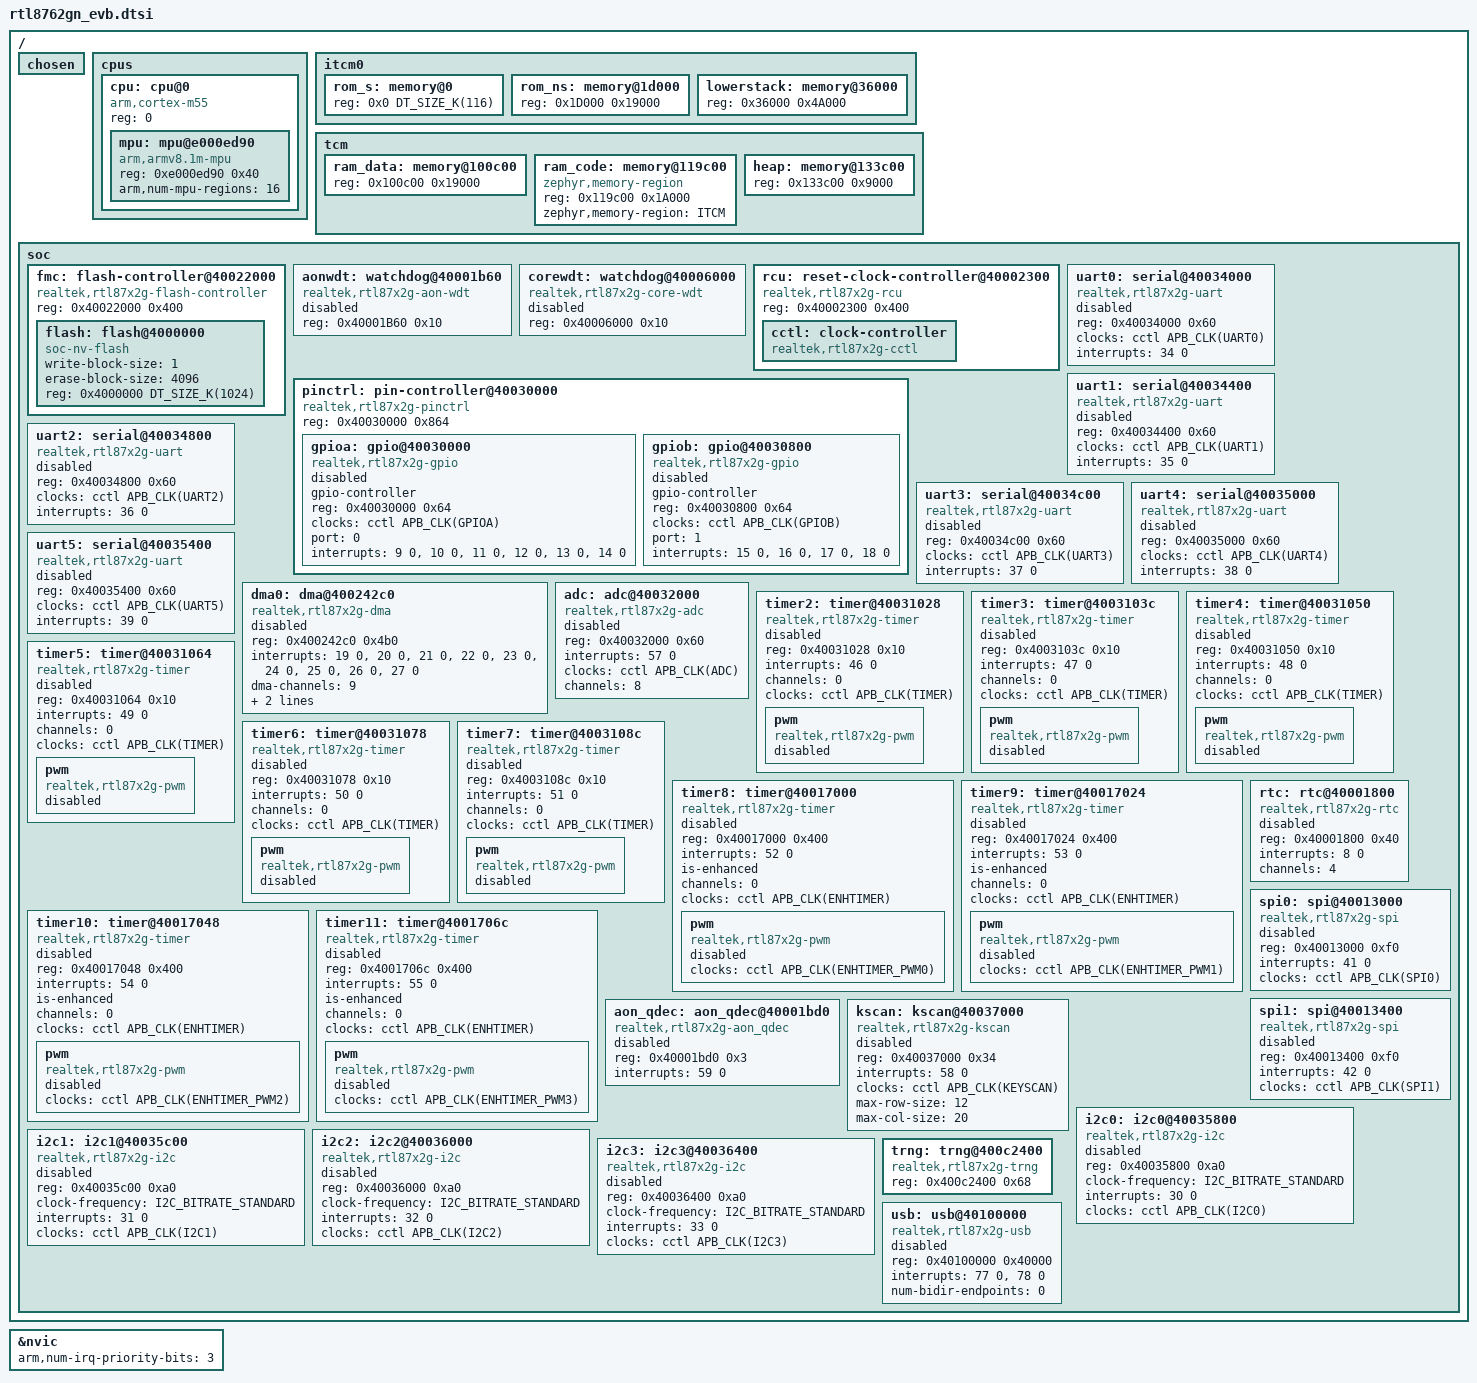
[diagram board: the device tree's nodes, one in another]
#include <mem.h>
#include <arm/armv8.1-m.dtsi>
#include <freq.h>
#include <dt-bindings/pinctrl/rtl87x2g-pinctrl.h>
#include <dt-bindings/clock/rtl87x2g-clocks.h>
#include <zephyr/dt-bindings/gpio/gpio.h>
#include <zephyr/dt-bindings/adc/adc.h>
#include <zephyr/dt-bindings/pwm/pwm.h>
#include <zephyr/dt-bindings/i2c/i2c.h>

/ {
	chosen {
	};

	cpus {
		#address-cells = <1>;
		#size-cells = <0>;

		cpu: cpu@0 {
			device_type = "cpu";
			compatible = "arm,cortex-m55";
			reg = <0>;
			#address-cells = <1>;
			#size-cells = <1>;

			mpu: mpu@e000ed90 {
				compatible = "arm,armv8.1m-mpu";
				reg = <0xe000ed90 0x40>;
				arm,num-mpu-regions = <16>;
			};
		};
	};

    itcm0 {
		#address-cells = <1>;
		#size-cells = <1>;

		rom_s: memory@0 {
			device_type = "secure rom code region";
			reg = <0x0 DT_SIZE_K(116)>;
		};
        rom_ns: memory@1d000 {
			device_type = "non-secure rom code region";
			reg = <0x1D000 0x19000>;
		};
		lowerstack: memory@36000 {
			device_type = "lowerstack code region";
			reg = <0x36000 0x4A000>;
		};
	};

	tcm {
		#address-cells = <1>;
		#size-cells = <1>;

		ram_data: memory@100c00 {
			device_type = "ram data region";
			reg = <0x100c00 0x19000>;
		};	
		ram_code: memory@119c00 {
			device_type = "ram code region";
			compatible = "zephyr,memory-region", "arm,itcm";
			reg = <0x119c00 0x1A000>;
			zephyr,memory-region = "ITCM";
		};
		heap: memory@133c00 {
			device_type = "heap region";
			reg = <0x133c00 0x9000>;
		};
	};

	soc {
		fmc: flash-controller@40022000 {
			compatible = "realtek,rtl87x2g-flash-controller";
			reg = <0x40022000 0x400>;
			#address-cells = <1>;
			#size-cells = <1>;
			status = "okay";

			flash: flash@4000000 {
				compatible = "soc-nv-flash";
				write-block-size = <1>;
				erase-block-size = <4096>;
				reg = <0x4000000 DT_SIZE_K(1024)>;
			};
		};

		aonwdt: watchdog@40001b60 {
			compatible = "realtek,rtl87x2g-aon-wdt";
			reg = <0x40001B60 0x10>;
			status = "disabled";
		};
		corewdt: watchdog@40006000 {
			compatible = "realtek,rtl87x2g-core-wdt";
			reg = <0x40006000 0x10>;
			status = "disabled";
		};

		rcu: reset-clock-controller@40002300 {
			compatible = "realtek,rtl87x2g-rcu";
			reg = <0x40002300 0x400>;
			status = "okay";

			cctl: clock-controller {
				compatible = "realtek,rtl87x2g-cctl";
				#clock-cells = <1>;
				status = "okay";
			};
		};

		pinctrl: pin-controller@40030000 {
			compatible = "realtek,rtl87x2g-pinctrl";
			#address-cells = <1>;
			#size-cells = <1>;
			reg = <0x40030000 0x864>;

			gpioa: gpio@40030000 {
				compatible = "realtek,rtl87x2g-gpio";
				gpio-controller;
				#gpio-cells = <2>;
				reg = <0x40030000 0x64>;
				clocks = <&cctl APB_CLK(GPIOA)>;
				port = <0>;
				interrupts = <9 0>, <10 0>, <11 0>, <12 0>, <13 0>, <14 0>;
				status = "disabled";
			};

			gpiob: gpio@40030800 {
				compatible = "realtek,rtl87x2g-gpio";
				gpio-controller;
				#gpio-cells = <2>;
				reg = <0x40030800 0x64>;
				clocks = <&cctl APB_CLK(GPIOB)>;
				port = <1>;
				interrupts = <15 0>, <16 0>, <17 0>, <18 0>;
				status = "disabled";
			};
		};

		uart0: serial@40034000 {
			compatible = "realtek,rtl87x2g-uart";
			reg = <0x40034000 0x60>;
			clocks = <&cctl APB_CLK(UART0)>;
			interrupts = <34 0>;
			status = "disabled";
		};

		uart1: serial@40034400 {
			compatible = "realtek,rtl87x2g-uart";
			reg = <0x40034400 0x60>;
			clocks = <&cctl APB_CLK(UART1)>;
			interrupts = <35 0>;
			status = "disabled";
		};

		uart2: serial@40034800 {
			compatible = "realtek,rtl87x2g-uart";
			reg = <0x40034800 0x60>;
			clocks = <&cctl APB_CLK(UART2)>;
			interrupts = <36 0>;
			status = "disabled";
		};

		uart3: serial@40034c00 {
			compatible = "realtek,rtl87x2g-uart";
			reg = <0x40034c00 0x60>;
			clocks = <&cctl APB_CLK(UART3)>;
			interrupts = <37 0>;
			status = "disabled";
		};

		uart4: serial@40035000 {
			compatible = "realtek,rtl87x2g-uart";
			reg = <0x40035000 0x60>;
			clocks = <&cctl APB_CLK(UART4)>;
			interrupts = <38 0>;
			status = "disabled";
		};

		uart5: serial@40035400 {
			compatible = "realtek,rtl87x2g-uart";
			reg = <0x40035400 0x60>;
			clocks = <&cctl APB_CLK(UART5)>;
			interrupts = <39 0>;
			status = "disabled";
		};

		dma0: dma@400242c0 {
			compatible = "realtek,rtl87x2g-dma";
			reg = <0x400242c0 0x4b0>;
			interrupts = <19 0>, <20 0>, <21 0>, <22 0>, <23 0>, 
				        <24 0>, <25 0>, <26 0>, <27 0>;
			dma-channels = <9>;
			clocks = <&cctl APB_CLK(GDMA)>;
			dma-port = <0>;
			#dma-cells = <3>;
			status = "disabled";
		};

		adc: adc@40032000 {
			compatible = "realtek,rtl87x2g-adc";
			reg = <0x40032000 0x60>;
			interrupts = <57 0>;
			clocks = <&cctl APB_CLK(ADC)>;
			channels = <8>;
			status = "disabled";
			#io-channel-cells = <1>;
		};

		timer2: timer@40031028 {
			compatible = "realtek,rtl87x2g-timer";
			reg = <0x40031028 0x10>;
			interrupts = <46 0>;
			channels = <0>;
			clocks = <&cctl APB_CLK(TIMER)>;
			status = "disabled";

			pwm {
				compatible = "realtek,rtl87x2g-pwm";
				status = "disabled";
				#pwm-cells = <3>;
			};
		};

		timer3: timer@4003103c {
			compatible = "realtek,rtl87x2g-timer";
			reg = <0x4003103c 0x10>;
			interrupts = <47 0>;
			channels = <0>;
			clocks = <&cctl APB_CLK(TIMER)>;
			status = "disabled";

			pwm {
				compatible = "realtek,rtl87x2g-pwm";
				status = "disabled";
				#pwm-cells = <3>;
			};
		};

		timer4: timer@40031050 {
			compatible = "realtek,rtl87x2g-timer";
			reg = <0x40031050 0x10>;
			interrupts = <48 0>;
			channels = <0>;
			clocks = <&cctl APB_CLK(TIMER)>;
			status = "disabled";

			pwm {
				compatible = "realtek,rtl87x2g-pwm";
				status = "disabled";
				#pwm-cells = <3>;
			};
		};

		timer5: timer@40031064 {
			compatible = "realtek,rtl87x2g-timer";
			reg = <0x40031064 0x10>;
			interrupts = <49 0>;
			channels = <0>;
			clocks = <&cctl APB_CLK(TIMER)>;
			status = "disabled";

			pwm {
				compatible = "realtek,rtl87x2g-pwm";
				status = "disabled";
				#pwm-cells = <3>;
			};
		};

		timer6: timer@40031078 {
			compatible = "realtek,rtl87x2g-timer";
			reg = <0x40031078 0x10>;
			interrupts = <50 0>;
			channels = <0>;
			clocks = <&cctl APB_CLK(TIMER)>;
			status = "disabled";

			pwm {
				compatible = "realtek,rtl87x2g-pwm";
				status = "disabled";
				#pwm-cells = <3>;
			};
		};

		timer7: timer@4003108c {
			compatible = "realtek,rtl87x2g-timer";
			reg = <0x4003108c 0x10>;
			interrupts = <51 0>;
			channels = <0>;
			clocks = <&cctl APB_CLK(TIMER)>;
			status = "disabled";

			pwm {
				compatible = "realtek,rtl87x2g-pwm";
				status = "disabled";
				#pwm-cells = <3>;
			};
		};

		timer8: timer@40017000 {
			compatible = "realtek,rtl87x2g-timer";
			reg = <0x40017000 0x400>;
			interrupts = <52 0>;
			is-enhanced;
			channels = <0>;
			clocks = <&cctl APB_CLK(ENHTIMER)>;
			status = "disabled";

			pwm {
				compatible = "realtek,rtl87x2g-pwm";
				status = "disabled";
				clocks = <&cctl APB_CLK(ENHTIMER_PWM0)>;
				#pwm-cells = <3>;
			};
		};

		timer9: timer@40017024 {
			compatible = "realtek,rtl87x2g-timer";
			reg = <0x40017024 0x400>;
			interrupts = <53 0>;
			is-enhanced;
			channels = <0>;
			clocks = <&cctl APB_CLK(ENHTIMER)>;
			status = "disabled";

			pwm {
				compatible = "realtek,rtl87x2g-pwm";
				status = "disabled";
				clocks = <&cctl APB_CLK(ENHTIMER_PWM1)>;
				#pwm-cells = <3>;
			};
		};

		timer10: timer@40017048 {
			compatible = "realtek,rtl87x2g-timer";
			reg = <0x40017048 0x400>;
			interrupts = <54 0>;
			is-enhanced;
			channels = <0>;
			clocks = <&cctl APB_CLK(ENHTIMER)>;
			status = "disabled";

			pwm {
				compatible = "realtek,rtl87x2g-pwm";
				status = "disabled";
				clocks = <&cctl APB_CLK(ENHTIMER_PWM2)>;
				#pwm-cells = <3>;
			};
		};

		timer11: timer@4001706c {
			compatible = "realtek,rtl87x2g-timer";
			reg = <0x4001706c 0x400>;
			interrupts = <55 0>;
			is-enhanced;
			channels = <0>;
			clocks = <&cctl APB_CLK(ENHTIMER)>;
			status = "disabled";

			pwm {
				compatible = "realtek,rtl87x2g-pwm";
				status = "disabled";
				clocks = <&cctl APB_CLK(ENHTIMER_PWM3)>;
				#pwm-cells = <3>;
			};
		};

		rtc: rtc@40001800 {
			compatible = "realtek,rtl87x2g-rtc";
			reg = <0x40001800 0x40>;
			interrupts = <8 0>;
			channels = <4>;
			status = "disabled";
		};

		aon_qdec: aon_qdec@40001bd0 {
			compatible = "realtek,rtl87x2g-aon_qdec";
			reg = <0x40001bd0 0x3>;
			interrupts = <59 0>;
			status = "disabled";
		};

		spi0: spi@40013000 {
			compatible = "realtek,rtl87x2g-spi";
			reg = <0x40013000 0xf0>;
			interrupts = <41 0>;
			clocks = <&cctl APB_CLK(SPI0)>;
			status = "disabled";
			#address-cells = <1>;
			#size-cells = <0>;
		};

		spi1: spi@40013400 {
			compatible = "realtek,rtl87x2g-spi";
			reg = <0x40013400 0xf0>;
			interrupts = <42 0>;
			clocks = <&cctl APB_CLK(SPI1)>;
			status = "disabled";
			#address-cells = <1>;
			#size-cells = <0>;
		};

		kscan: kscan@40037000 {
			compatible = "realtek,rtl87x2g-kscan";
			reg = <0x40037000 0x34>;
			interrupts = <58 0>;
			clocks = <&cctl APB_CLK(KEYSCAN)>;
			max-row-size = <12>;
			max-col-size = <20>;
			status = "disabled";
		};

		i2c0: i2c0@40035800 {
			compatible = "realtek,rtl87x2g-i2c";
			reg = <0x40035800 0xa0>;
			clock-frequency = <I2C_BITRATE_STANDARD>;
			#address-cells = <1>;
			#size-cells = <0>;
			interrupts = <30 0>;
			clocks = <&cctl APB_CLK(I2C0)>;
			status = "disabled";
		};

		i2c1: i2c1@40035c00 {
			compatible = "realtek,rtl87x2g-i2c";
			reg = <0x40035c00 0xa0>;
			clock-frequency = <I2C_BITRATE_STANDARD>;
			#address-cells = <1>;
			#size-cells = <0>;
			interrupts = <31 0>;
			clocks = <&cctl APB_CLK(I2C1)>;
			status = "disabled";
		};

		i2c2: i2c2@40036000 {
			compatible = "realtek,rtl87x2g-i2c";
			reg = <0x40036000 0xa0>;
			clock-frequency = <I2C_BITRATE_STANDARD>;
			#address-cells = <1>;
			#size-cells = <0>;
			interrupts = <32 0>;
			clocks = <&cctl APB_CLK(I2C2)>;
			status = "disabled";
		};

		i2c3: i2c3@40036400 {
			compatible = "realtek,rtl87x2g-i2c";
			reg = <0x40036400 0xa0>;
			clock-frequency = <I2C_BITRATE_STANDARD>;
			#address-cells = <1>;
			#size-cells = <0>;
			interrupts = <33 0>;
			clocks = <&cctl APB_CLK(I2C3)>;
			status = "disabled";
		};

		trng: trng@400c2400 {
			compatible = "realtek,rtl87x2g-trng";
			reg = <0x400c2400 0x68>;
			status = "okay";
        };

		usb: usb@40100000 {
			compatible = "realtek,rtl87x2g-usb";
			reg = <0x40100000 0x40000>;
			interrupts = <77 0>, <78 0>;
			num-bidir-endpoints = <0>;
			status = "disabled";
		};
	};

};

&nvic {
	arm,num-irq-priority-bits = <3>;
};
